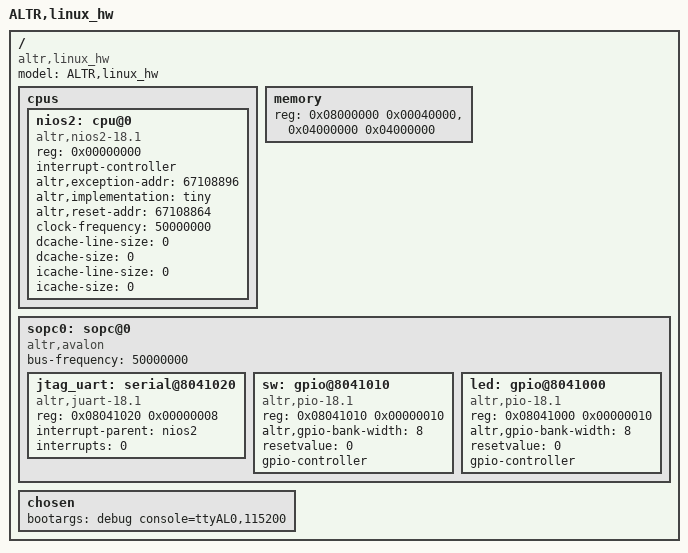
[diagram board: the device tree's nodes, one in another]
/*
 * This devicetree is generated by sopc2dts version rel_14.0_RC3-44-g97a55b1 on Sun Sep 06 17:14:00 CEST 2020
 * Sopc2dts is written by Walter Goossens <waltergoossens@home.nl>
 * in cooperation with the nios2 community <nios2-dev@lists.rocketboards.org>
 */
/dts-v1/;

/ {
	model = "ALTR,linux_hw";
	compatible = "altr,linux_hw";
	#address-cells = <1>;
	#size-cells = <1>;

	cpus {
		#address-cells = <1>;
		#size-cells = <0>;

		nios2: cpu@0 {
			device_type = "cpu";
			compatible = "altr,nios2-18.1", "altr,nios2-1.1";
			reg = <0x00000000>;
			interrupt-controller;
			#interrupt-cells = <1>;
			altr,exception-addr = <67108896>;	/* embeddedsw.dts.params.altr,exception-addr type NUMBER */
			altr,implementation = "tiny";	/* embeddedsw.dts.params.altr,implementation type STRING */
			altr,reset-addr = <67108864>;	/* embeddedsw.dts.params.altr,reset-addr type NUMBER */
			clock-frequency = <50000000>;	/* embeddedsw.dts.params.clock-frequency type NUMBER */
			dcache-line-size = <0>;	/* embeddedsw.dts.params.dcache-line-size type NUMBER */
			dcache-size = <0>;	/* embeddedsw.dts.params.dcache-size type NUMBER */
			icache-line-size = <0>;	/* embeddedsw.dts.params.icache-line-size type NUMBER */
			icache-size = <0>;	/* embeddedsw.dts.params.icache-size type NUMBER */
		}; //end cpu@0 (nios2)
	}; //end cpus

	memory {
		device_type = "memory";
		reg = <0x08000000 0x00040000>,
			<0x04000000 0x04000000>;
	}; //end memory

	sopc0: sopc@0 {
		device_type = "soc";
		ranges;
		#address-cells = <1>;
		#size-cells = <1>;
		compatible = "altr,avalon", "simple-bus";
		bus-frequency = <50000000>;

		jtag_uart: serial@8041020 {
			compatible = "altr,juart-18.1", "altr,juart-1.0";
			reg = <0x08041020 0x00000008>;
			interrupt-parent = <&nios2>;
			interrupts = <0>;
		}; //end serial@8041020 (jtag_uart)

		sw: gpio@8041010 {
			compatible = "altr,pio-18.1", "altr,pio-1.0";
			reg = <0x08041010 0x00000010>;
			altr,gpio-bank-width = <8>;	/* embeddedsw.dts.params.altr,gpio-bank-width type NUMBER */
			resetvalue = <0>;	/* embeddedsw.dts.params.resetvalue type NUMBER */
			#gpio-cells = <2>;
			gpio-controller;
		}; //end gpio@8041010 (sw)

		led: gpio@8041000 {
			compatible = "altr,pio-18.1", "altr,pio-1.0";
			reg = <0x08041000 0x00000010>;
			altr,gpio-bank-width = <8>;	/* embeddedsw.dts.params.altr,gpio-bank-width type NUMBER */
			resetvalue = <0>;	/* embeddedsw.dts.params.resetvalue type NUMBER */
			#gpio-cells = <2>;
			gpio-controller;
		}; //end gpio@8041000 (led)
	}; //end sopc@0 (sopc0)

	chosen {
		bootargs = "debug console=ttyAL0,115200";
	}; //end chosen
}; //end /
